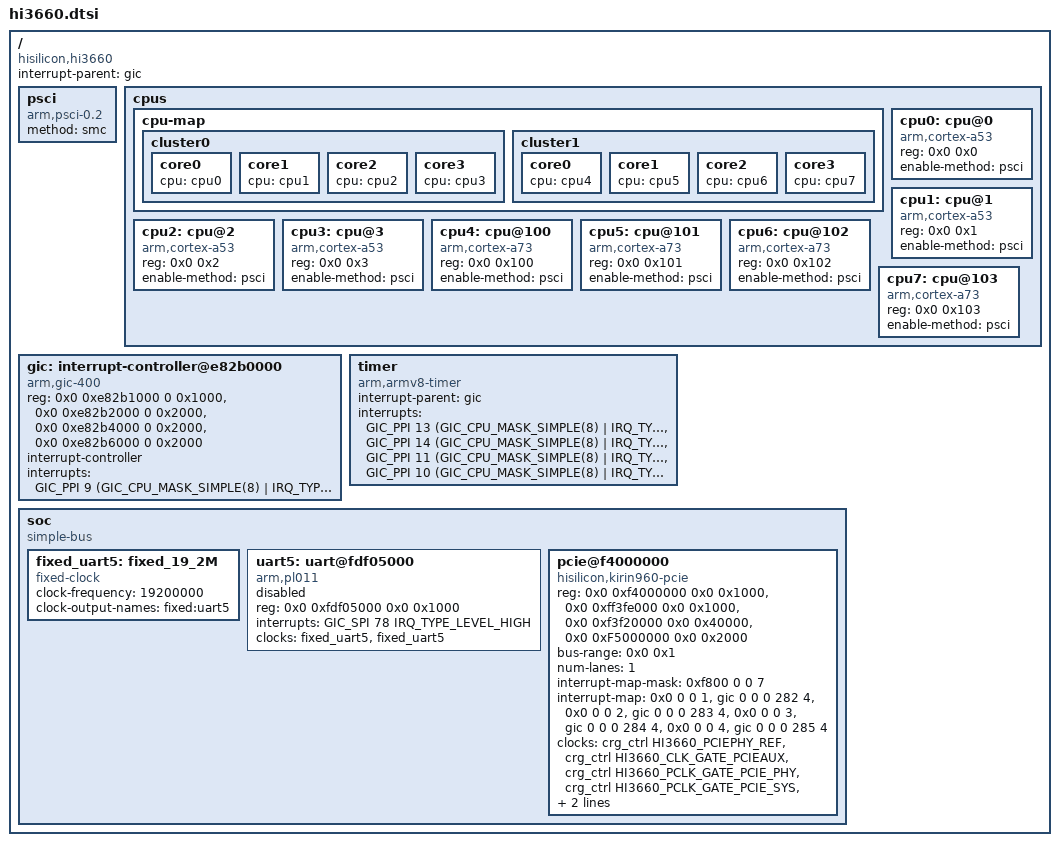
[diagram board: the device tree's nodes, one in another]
/*
 * dts file for Hisilicon Hi3660 SoC
 *
 * Copyright (C) 2016, Hisilicon Ltd.
 */

#include <dt-bindings/interrupt-controller/arm-gic.h>

/ {
	compatible = "hisilicon,hi3660";
	interrupt-parent = <&gic>;
	#address-cells = <2>;
	#size-cells = <2>;

	psci {
		compatible = "arm,psci-0.2";
		method = "smc";
	};

	cpus {
		#address-cells = <2>;
		#size-cells = <0>;

		cpu-map {
			cluster0 {
				core0 {
					cpu = <&cpu0>;
				};
				core1 {
					cpu = <&cpu1>;
				};
				core2 {
					cpu = <&cpu2>;
				};
				core3 {
					cpu = <&cpu3>;
				};
			};
			cluster1 {
				core0 {
					cpu = <&cpu4>;
				};
				core1 {
					cpu = <&cpu5>;
				};
				core2 {
					cpu = <&cpu6>;
				};
				core3 {
					cpu = <&cpu7>;
				};
			};
		};

		cpu0: cpu@0 {
			compatible = "arm,cortex-a53", "arm,armv8";
			device_type = "cpu";
			reg = <0x0 0x0>;
			enable-method = "psci";
		};

		cpu1: cpu@1 {
			compatible = "arm,cortex-a53", "arm,armv8";
			device_type = "cpu";
			reg = <0x0 0x1>;
			enable-method = "psci";
		};

		cpu2: cpu@2 {
			compatible = "arm,cortex-a53", "arm,armv8";
			device_type = "cpu";
			reg = <0x0 0x2>;
			enable-method = "psci";
		};

		cpu3: cpu@3 {
			compatible = "arm,cortex-a53", "arm,armv8";
			device_type = "cpu";
			reg = <0x0 0x3>;
			enable-method = "psci";
		};

		cpu4: cpu@100 {
			compatible = "arm,cortex-a73", "arm,armv8";
			device_type = "cpu";
			reg = <0x0 0x100>;
			enable-method = "psci";
		};

		cpu5: cpu@101 {
			compatible = "arm,cortex-a73", "arm,armv8";
			device_type = "cpu";
			reg = <0x0 0x101>;
			enable-method = "psci";
		};

		cpu6: cpu@102 {
			compatible = "arm,cortex-a73", "arm,armv8";
			device_type = "cpu";
			reg = <0x0 0x102>;
			enable-method = "psci";
		};

		cpu7: cpu@103 {
			compatible = "arm,cortex-a73", "arm,armv8";
			device_type = "cpu";
			reg = <0x0 0x103>;
			enable-method = "psci";
		};
	};

	gic: interrupt-controller@e82b0000 {
		compatible = "arm,gic-400";
		reg = <0x0 0xe82b1000 0 0x1000>, /* GICD */
		      <0x0 0xe82b2000 0 0x2000>, /* GICC */
		      <0x0 0xe82b4000 0 0x2000>, /* GICH */
		      <0x0 0xe82b6000 0 0x2000>; /* GICV */
		#address-cells = <0>;
		#interrupt-cells = <3>;
		interrupt-controller;
		interrupts = <GIC_PPI 9 (GIC_CPU_MASK_SIMPLE(8) |
					 IRQ_TYPE_LEVEL_HIGH)>;
	};

	timer {
		compatible = "arm,armv8-timer";
		interrupt-parent = <&gic>;
		interrupts = <GIC_PPI 13 (GIC_CPU_MASK_SIMPLE(8) |
					  IRQ_TYPE_LEVEL_LOW)>,
			     <GIC_PPI 14 (GIC_CPU_MASK_SIMPLE(8) |
					  IRQ_TYPE_LEVEL_LOW)>,
			     <GIC_PPI 11 (GIC_CPU_MASK_SIMPLE(8) |
					  IRQ_TYPE_LEVEL_LOW)>,
			     <GIC_PPI 10 (GIC_CPU_MASK_SIMPLE(8) |
					  IRQ_TYPE_LEVEL_LOW)>;
	};

	soc {
		compatible = "simple-bus";
		#address-cells = <2>;
		#size-cells = <2>;
		ranges;

		fixed_uart5: fixed_19_2M {
			compatible = "fixed-clock";
			#clock-cells = <0>;
			clock-frequency = <19200000>;
			clock-output-names = "fixed:uart5";
		};

		uart5: uart@fdf05000 {
			compatible = "arm,pl011", "arm,primecell";
			reg = <0x0 0xfdf05000 0x0 0x1000>;
			interrupts = <GIC_SPI 78 IRQ_TYPE_LEVEL_HIGH>;
			clocks = <&fixed_uart5 &fixed_uart5>;
			clock-names = "uartclk", "apb_pclk";
			status = "disabled";
		};

		pcie@f4000000 {
			compatible = "hisilicon,kirin960-pcie";
			reg =  <0x0 0xf4000000 0x0 0x1000>,
				<0x0 0xff3fe000 0x0 0x1000>,
				<0x0 0xf3f20000 0x0 0x40000>,
				<0x0 0xF5000000 0x0 0x2000>;
			reg-names = "dbi", "apb", "phy", "config";
			bus-range = <0x0  0x1>;
			#address-cells = <3>;
			#size-cells = <2>;
			device_type = "pci";
			ranges = <0x02000000 0x0 0x00000000 0x0
				0xf6000000 0x0 0x2000000>;
			num-lanes = <1>;
			#interrupt-cells = <1>;
			interrupt-map-mask = <0xf800 0 0 7>;
			interrupt-map = <0x0 0 0 1 &gic 0 0 0 282 4>,
				<0x0 0 0 2 &gic 0 0 0  283 4>,
				<0x0 0 0 3 &gic 0 0 0  284 4>,
				<0x0 0 0 4 &gic 0 0 0  285 4>;
			clocks = <&crg_ctrl HI3660_PCIEPHY_REF>,
				<&crg_ctrl HI3660_CLK_GATE_PCIEAUX>,
				<&crg_ctrl HI3660_PCLK_GATE_PCIE_PHY>,
				<&crg_ctrl HI3660_PCLK_GATE_PCIE_SYS>,
				<&crg_ctrl HI3660_ACLK_GATE_PCIE>;
			clock-names = "pcie_phy_ref", "pcie_aux",
				"pcie_apb_phy", "pcie_apb_sys", "pcie_aclk";
			reset-gpios = <&gpio11 1 0 >;
			status = "ok";
		};
	};
};
